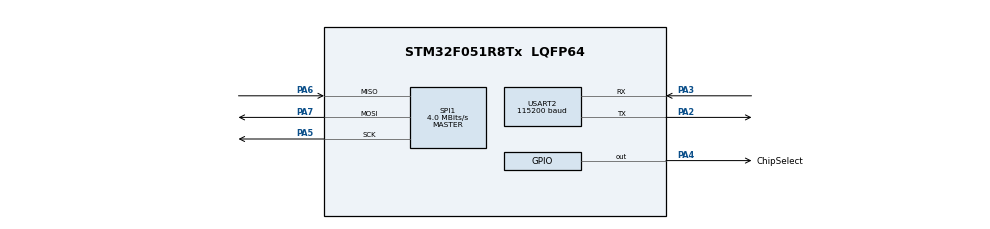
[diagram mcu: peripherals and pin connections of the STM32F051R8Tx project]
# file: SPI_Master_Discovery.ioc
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Mcu.Family=STM32F0
Mcu.Name=STM32F051R8Tx
Mcu.Package=LQFP64
PA2.Mode=Asynchronous
PA2.Signal=USART2_TX
PA3.Mode=Asynchronous
PA3.Signal=USART2_RX
PA4.GPIO_Label=ChipSelect
PA4.Signal=GPIO_Output
PA5.Mode=Full_Duplex_Master
PA5.Signal=SPI1_SCK
PA6.Mode=Full_Duplex_Master
PA6.Signal=SPI1_MISO
PA7.Mode=Full_Duplex_Master
PA7.Signal=SPI1_MOSI
ProjectManager.HeapSize=0x200
ProjectManager.StackSize=0x400
ProjectManager.TargetToolchain=STM32CubeIDE
SPI1.CalculateBaudRate=4.0 MBits/s
SPI1.DataSize=SPI_DATASIZE_8BIT
SPI1.Direction=SPI_DIRECTION_2LINES
SPI1.Mode=SPI_MODE_MASTER
SPI1.VirtualType=VM_MASTER
USART2.BaudRate=115200
USART2.VirtualMode-Asynchronous=VM_ASYNC
board=custom

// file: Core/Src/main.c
/* USER CODE BEGIN Header */
/**
  ******************************************************************************
  * @file           : main.c
  * @brief          : Main program body
  ******************************************************************************
  * @attention
  *
  * Copyright (c) 2025 STMicroelectronics.
  * All rights reserved.
  *
  * This software is licensed under terms that can be found in the LICENSE file
  * in the root directory of this software component.
  * If no LICENSE file comes with this software, it is provided AS-IS.
  *
  ******************************************************************************
  */
/* USER CODE END Header */
#include "main.h"
#include "spi.h"
#include "usart.h"
#include "gpio.h"

void SystemClock_Config(void);

/* USER CODE BEGIN 0 */
int __io_putchar(int ch)
{
    HAL_UART_Transmit(&huart2, (uint8_t*)&ch, 1, HAL_MAX_DELAY);
    return 1;
}
/* USER CODE END 0 */

int main(void)
{

  /* MCU Configuration--------------------------------------------------------*/

  /* Reset of all peripherals, Initializes the Flash interface and the Systick. */
  HAL_Init();

  /* Configure the system clock */
  SystemClock_Config();

  /* Initialize all configured peripherals */
  MX_GPIO_Init();
  MX_SPI1_Init();
  MX_USART2_UART_Init();
  /* USER CODE BEGIN 2 */
  float received_temp = 0;
  //uint8_t temp_bytes[4];
  /* USER CODE END 2 */

  /* Infinite loop */
  /* USER CODE BEGIN WHILE */
  while (1)
  {
	  printf("____________________________________________________________________\r\n");
	  HAL_GPIO_WritePin(ChipSelect_GPIO_Port, ChipSelect_Pin, GPIO_PIN_RESET); // Aktywacja CS
	  uint8_t temp_bytes[4] = {0}; // Wyzerowanie bufora przed odbiorem
	  HAL_SPI_Receive(&hspi1, temp_bytes, sizeof(temp_bytes), HAL_MAX_DELAY);
	  HAL_GPIO_WritePin(ChipSelect_GPIO_Port, ChipSelect_Pin, GPIO_PIN_SET); // Dezaktywacja CS
	  memcpy(&received_temp, temp_bytes, sizeof(received_temp));
	  printf("Temperatura: %.4f*C\r\n", received_temp);
	  printf("Received bytes: %02X %02X %02X %02X\r\n", temp_bytes[0], temp_bytes[1], temp_bytes[2], temp_bytes[3]);
	  HAL_Delay(1000); // Krótka przerwa by Slave miał czas na przygotowanie danych
    /* USER CODE END WHILE */

  }
}

void SystemClock_Config(void)
{
  RCC_OscInitTypeDef RCC_OscInitStruct = {0};
  RCC_ClkInitTypeDef RCC_ClkInitStruct = {0};

  /** Initializes the RCC Oscillators according to the specified parameters
  * in the RCC_OscInitTypeDef structure.
  */
  RCC_OscInitStruct.OscillatorType = RCC_OSCILLATORTYPE_HSI;
  RCC_OscInitStruct.HSIState = RCC_HSI_ON;
  RCC_OscInitStruct.HSICalibrationValue = RCC_HSICALIBRATION_DEFAULT;
  RCC_OscInitStruct.PLL.PLLState = RCC_PLL_NONE;
  if (HAL_RCC_OscConfig(&RCC_OscInitStruct) != HAL_OK)
  {
    Error_Handler();
  }

  /** Initializes the CPU, AHB and APB buses clocks
  */
  RCC_ClkInitStruct.ClockType = RCC_CLOCKTYPE_HCLK|RCC_CLOCKTYPE_SYSCLK
                              |RCC_CLOCKTYPE_PCLK1;
  RCC_ClkInitStruct.SYSCLKSource = RCC_SYSCLKSOURCE_HSI;
  RCC_ClkInitStruct.AHBCLKDivider = RCC_SYSCLK_DIV1;
  RCC_ClkInitStruct.APB1CLKDivider = RCC_HCLK_DIV1;

  if (HAL_RCC_ClockConfig(&RCC_ClkInitStruct, FLASH_LATENCY_0) != HAL_OK)
  {
    Error_Handler();
  }
}

void Error_Handler(void)
{
  __disable_irq();
  while (1)
  {
  }
}
